# YTM32B1ME1 register map
Vendor: YTMicro; File version: 1.0
CPU: CM33 r0p4, little endian, MPU, FPU, 2 interrupt priority bits
Registers are 32-bit, read-write, reset 0x0 unless marked. A register's access mark holds for its fields unless they carry their own. Offsets are from the block's base; [hi:lo] are bit positions; {n}, {i} and the like mark numbered series.

## PCU — Power control unit
Base 0x401F8000; register names take the prefix PCU_
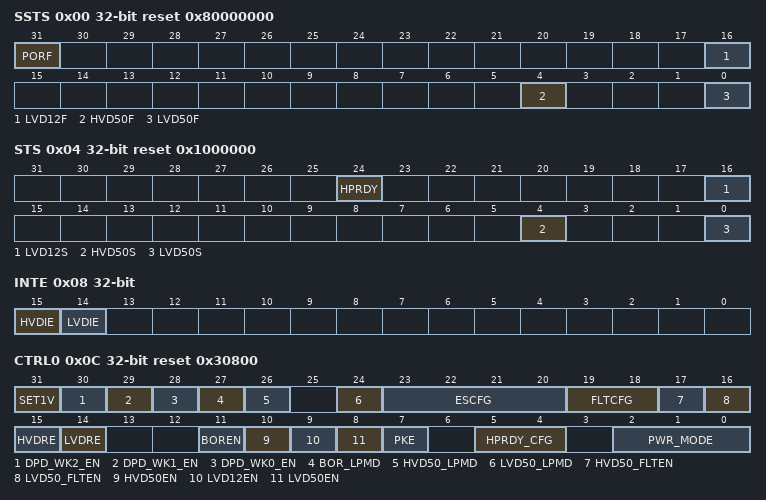
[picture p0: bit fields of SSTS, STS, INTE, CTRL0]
0x00 SSTS reset 0x80000000
  [31] PORF — Indicate the POR happens after the flag is cleared. Write 1 to this bit will clear it.
    0=No power-on reset event has occurred; 1=Power-on reset event has occurred
  [16] LVD12F — Indicate a low voltage event has been detected on VDD12. Write 1 to this bit will clear it.
    0=No low voltage event on VDD12 has been detected; 1=High voltage event on VDD12 has been detected
  [4] HVD50F — Indicate a high voltage event has been detected on VDD50. Write 1 to this bit will clear it.
    0=No high voltage event on VDD50 has been detected; 1=High voltage event on VDD50 has been detected
  [0] LVD50F — Indicate a low voltage event has been detected on VDD50. Write 1 to this bit will clear it.
    0=No low voltage event on VDD50 has been detected; 1=Low voltage event on VDD50 has been detected
0x04 STS ro reset 0x1000000
  [24] HPRDY rw — When set, it means PMC is in high power mode. FIRC must work in high power mode.
    0=PMC is in low power mode; 1=PMC is in high power mode
  [16] LVD12S rw — Indicate the status of low voltage detect on VDD12 power domain
    0=Voltage on VDD12 is above low-votage detect threshold; 1=Voltage on VDD12 is below low-votage detect threshold
  [4] HVD50S rw — Indicate the status of high voltage detect on VDD50 power domain
    0=Voltage on VDD50 is below high-votage detect threshold; 1=Voltage on VDD50 is above high-votage detect threshold
  [0] LVD50S rw — Indicate the status of low voltage detect on VDD50 power domain
    0=Voltage on VDD50 is above low-votage detect threshold; 1=Voltage on VDD50 is below low-votage detect threshold
0x08 INTE
  [15] HVDIE — This bit enables hardware interrupt request if HVD50F is set
    0=HVD hardware interrupt is disabled; 1=Request a HVD hardware interrupt when HVD50F is set
  [14] LVDIE — This bit enables hardware interrupt request if LVD12F or LVD50F is set
    0=LVD hardware interrupt is disabled; 1=Request a LVD hardware interrupt when LVD12F or LVD50F is set
0x0C CTRL0 reset 0x30800
  [31] SET1V — When set, the core supply will change to 1v if PMC is in low power mode.
    0=Core supply is 1.2v; 1=Set core supply to 1v
  [30] DPD_WK2_EN — This bit enables wakeup source 2 for deep powerdown mode. Should be disable when enter power down mode.
    0=Wakeup source 2 is disabled; 1=Wakeup source 2 is enabled. PTC6 falling edge can wake up chip from deep powerdown mode.
  [29] DPD_WK1_EN — This bit enables wakeup source 1 for deep powerdown mode. Should be disable when enter power down mode.
    0=Wakeup source 1 is disabled; 1=Wakeup source 1 is enabled. PTC2 falling edge can wake up chip from deep powerdown mode.
  [28] DPD_WK0_EN — This bit enables wakeup source 0 for deep powerdown mode. Should be disable when enter power down mode.
    0=Wakeup source 0 is disabled; 1=Wakeup source 0 is enabled. PTC0 falling edge can wake up chip from deep powerdown mode.
  [27] BOR_LPMD — This bit makes BOR circuit in low power mode.
    0=BOR is not in low power mode; 1=BOR in in low power mode
  [26] HVD50_LPMD — This bit makes HVD50 circuit in low power mode.
    0=HVD50 is not in low power mode; 1=HVD50 in in low power mode
  [24] LVD50_LPMD — This bit makes LVD50 circuit in low power mode.
    0=LVD50 is not in low power mode; 1=LVD50 in in low power mode
  [23:20] ESCFG — This field configures the energy saving efficiency for BOR, HVD50 adn LVD50 . All values except those in the range described below are reserved.
    0=0.10% of normal mode, Sampling period=512ms; 1=0.20% of normal mode, Sampling period=256ms; 2=0.40% of normal mode, Sampling period=128ms; 3=0.80% of normal mode, Sampling period=64ms; 4=1.56% of normal mode, Sampling period=32ms; 5=3.10% of normal mode, Sampling period=16ms; 6=6.25% of normal mode, Sampling period=8ms; 7=12.5% of normal mode, Sampling period=4ms; 8=25.0% of normal mode, Sampling period=2ms; 9=50.0% of normal mode, Sampling period=1ms
  [19:18] FLTCFG — There is an optional digital glitch filter for LVD50 and HVD50. The glitches that width is shorter than (FLTCFG+1)*(the period of LPOCLK) can be filtered.
  [17] HVD50_FLTEN — When this bit is set, HVD50 glitch filter is enabled. The filter is also enabled if HVD50_LPMD is set no matter HVD50_FLTEN is set or not.
    0=HVD50S is not filtered by glitch filter if HVD50_LPMD is not set; 1=HVD50S is filtered by glitch filter
  [16] LVD50_FLTEN — When this bit is set, LVD50 glitch filter is enabled. The filter is also enabled if LVD50_LPMD is set no matter LVD50_FLTEN is set or not.
    0=LVD50S is not filtered by glitch filter if LVD50_LPMD is not set; 1=LVD50S is filtered by glitch filter
  [15] HVDRE — This bit enables hardware reset request if HVD50F is set
    0=HVD hardware reset is disabled; 1=Request a HVD hardware reset when HVD50F is set
  [14] LVDRE — This bit enables hardware reset request if LVD12F or LVD50F is set
    0=LVD hardware reset is disabled; 1=Request a LVD hardware reset when LVD12F or LVD50F is set
  [11] BOREN — BOREN enables the BOR module. When BOR is enabled, a bor reset occurs when the chip power supply voltage falls below BOR threshold(about 2.2V)
    0=BOR is disabled; 1=BOR is enabled
  [10] HVD50EN — HVD50EN enables the HVD50 module. When HVD50 is enabled, a HVD flag occurs when the chip power supply voltage raise above HVD50 threshold.
    0=HVD50 is disabled; 1=HVD50 is enabled
  [9] LVD12EN — LVD12EN enables the LVD12 module. When LVD12 is enabled, a LVD flag occurs when the core supply voltage falls below LVD12 threshold.
    0=LVD12 is disabled; 1=LVD12 is enabled
  [8] LVD50EN — LVD50EN enables the LVD50 module. When LVD50 is enabled, a LVD flag occurs when the chip power supply voltage falls below LVD50 threshold.
    0=LVD50 is disabled; 1=LVD50 is enabled
  [7] PKE — This bit is to control PAD state when wakeup from powerdown mode.
    0=PAD state is reseted when wakeup from powerdown mode; 1=PAD state is kept when wakeup from powerdown mode until PKE bit is cleared to 0
  [5:4] HPRDY_CFG — When HPRDY is in posedge sate, it will delay for some time to be 1. The delay length is determined by the configured value.
    0=The delay length is 80us; 1=The delay length is 160us; 2=The delay length is 240us; 3=The delay length is 320us
  [2:0] PWR_MODE — This field controls PMC to enter various power mode. Which mode will enter is determined by the configured value. 0b000 - Normal run mode 0b001 - Standby mode 0b010 - Powerdown mode 0b011 - Deep powerdown mode 100b - Reserved
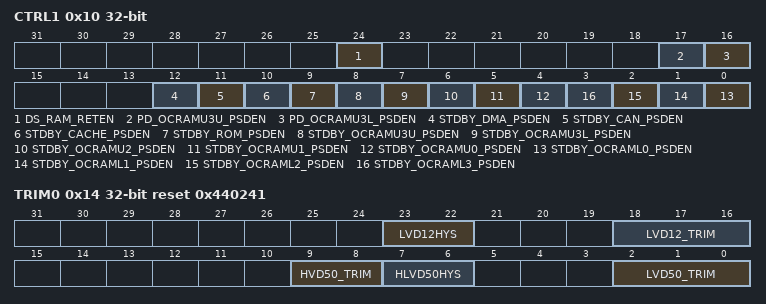
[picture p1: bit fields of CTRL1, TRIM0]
0x10 CTRL1
  [24] DS_RAM_RETEN — This bit controls whether all the RAMs enter retention state when chip enters deepsleep mode.
    0=RAMs don't enter retention state when chip enters deepsleep mode; 1=RAMs enter retention state when chip enters deepsleep mode
  [17] PD_OCRAMU3U_PSDEN — This bit controls whether OCRAMU3U enter power shut down state when chip enters powerdown mode.
    0=OCRAMU3U doesn't enter power shut down state when chip enters powerdown mode; 1=OCRAMU3U enters power shut down state when chip enters powerdown mode
  [16] PD_OCRAMU3L_PSDEN — This bit controls whether OCRAMU3L enter power shut down state when chip enters powerdown mode.
    0=OCRAMU3L doesn't enter power shut down state when chip enters powerdown mode; 1=OCRAMU3L enters power shut down state when chip enters powerdown mode
  [12] STDBY_DMA_PSDEN — This bit controls whether DMA RAM enter power shutdown state when chip enters statndby mode.
    0=DMA RAM doesn't enter power shutdown state when chip enters standby mode; 1=DMA RAM enters power shutdown state when chip enters standby mode
  [11] STDBY_CAN_PSDEN — This bit controls whether CAN RAM enter power shutdown state when chip enters statndby mode.
    0=CAN RAM doesn't enter power shutdown state when chip enters standby mode; 1=CAN RAM enters power shutdown state when chip enters standby mode
  [10] STDBY_CACHE_PSDEN — This bit controls whether CACHE RAM enter power shutdown state when chip enters statndby mode.
    0=CACHE RAM doesn't enter power shutdown state when chip enters standby mode; 1=CACHE RAM enters power shutdown state when chip enters standby mode
  [9] STDBY_ROM_PSDEN — This bit controls whether ROM enter power shutdown state when chip enters statndby mode.
    0=ROM doesn't enter power shutdown state when chip enters standby mode; 1=ROM enters power shutdown state when chip enters standby mode
  [8] STDBY_OCRAMU3U_PSDEN — This bit controls whether OCRAMU3U enter power shutdown state when chip enters statndby mode.
    0=OCRAMU3U doesn't enter power shutdown state when chip enters standby mode; 1=OCRAMU3U enters power shutdown state when chip enters standby mode
  [7] STDBY_OCRAMU3L_PSDEN — This bit controls whether OCRAMU3L enter power shutdown state when chip enters statndby mode.
    0=OCRAMU3L doesn't enter power shutdown state when chip enters standby mode; 1=OCRAMU3L enters power shutdown state when chip enters standby mode
  [6] STDBY_OCRAMU2_PSDEN — This bit controls whether OCRAMU2 enter power shutdown state when chip enters statndby mode.
    0=OCRAMU2 doesn't enter power shutdown state when chip enters standby mode; 1=OCRAMU2 enters power shutdown state when chip enters standby mode
  [5] STDBY_OCRAMU1_PSDEN — This bit controls whether OCRAMU1 enter power shutdown state when chip enters statndby mode.
    0=OCRAMU1 doesn't enter power shutdown state when chip enters standby mode; 1=OCRAMU1 enters power shutdown state when chip enters standby mode
  [4] STDBY_OCRAMU0_PSDEN — This bit controls whether OCRAMU0 enter power shutdown state when chip enters statndby mode.
    0=OCRAMU0 doesn't enter power shutdown state when chip enters standby mode; 1=OCRAMU0 enters power shutdown state when chip enters standby mode
  [n] STDBY_OCRAML{n}_PSDEN (n=0..3) — This bit controls whether OCRAML{n} enter power shutdown state when chip enters statndby mode.
    0=OCRAML{n} doesn't enter power shutdown state when chip enters standby mode; 1=OCRAML{n} enters power shutdown state when chip enters standby mode
0x14 TRIM0 reset 0x440241
  [23:22] LVD12HYS — This field configures the LVD12 hysteresis.
    0=0mV; 1=+-1.25%; 2=+-2.6%; 3=+-4.1%
  [18:16] LVD12_TRIM — This field configures the LVD12 threshold voltage.
    0=821mV; 1=847mV; 2=873mV; 3=899mV; 4=926mV; 5=953mV; 6=980mV; 7=1006mV
  [9:8] HVD50_TRIM — This field configures the HVD50 threshold voltage.
    0=5.5V; 1=5.833V; 2=6.166V; 3=6.5V
  [7:6] HLVD50HYS — This field configures the LVD50 hysteresis.
    0=0mV; 1=+-2%; 2=+-4.2%; 3=+-8.4%
  [2:0] LVD50_TRIM — This field configures the LVD50 threshold voltage.
    0=Reserve; 1=2.5V; 2=2.833V; 3=3.166V; 4=3.496V; 5=3.829V; 6=4.162V; 7=4.5V
